VERSION ""

NS_ :

BS_:

BU_: XXX

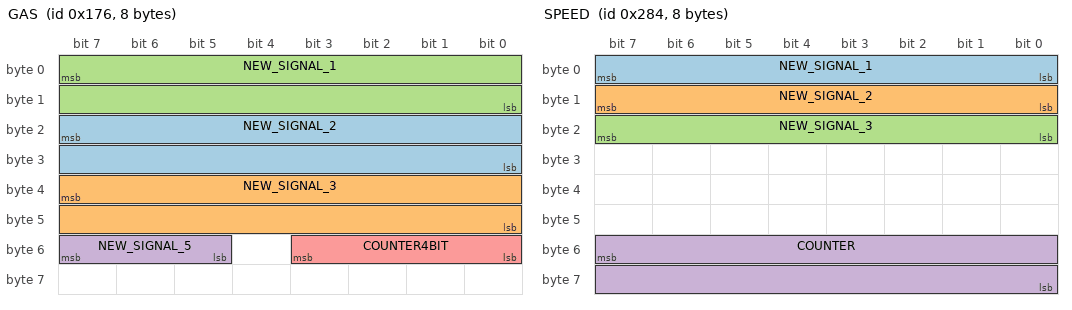
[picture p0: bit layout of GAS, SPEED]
BO_ 374 GAS: 8 XXX
 SG_ NEW_SIGNAL_2 : 23|16@0+ (1,0) [0|65535] "" XXX
 SG_ NEW_SIGNAL_3 : 39|16@0+ (1,0) [0|65535] "" XXX
 SG_ NEW_SIGNAL_1 : 7|16@0+ (1,0) [0|65535] "" XXX
 SG_ NEW_SIGNAL_5 : 55|3@0+ (1,0) [0|7] "" XXX
 SG_ COUNTER4BIT : 48|4@1+ (1,0) [0|15] "" XXX

BO_ 644 SPEED: 8 XXX
 SG_ NEW_SIGNAL_1 : 7|8@0+ (1,0) [0|65535] "" XXX
 SG_ NEW_SIGNAL_2 : 15|8@0+ (1,0) [0|255] "" XXX
 SG_ NEW_SIGNAL_3 : 23|8@0+ (1,0) [0|255] "" XXX
 SG_ COUNTER : 55|16@0+ (1,0) [0|65535] "" XXX

BO_ 658 NEW_MSG_2: 8 XXX
 SG_ NEW_SIGNAL_1 : 15|8@0+ (1,0) [0|255] "" XXX
 SG_ NEW_SIGNAL_2 : 7|8@0+ (1,0) [0|255] "" XXX
 SG_ NEW_SIGNAL_3 : 23|0@0+ (1,0) [0|255] "" XXX

BO_ 768 STEERING: 8 XXX
 SG_ STEER_TORQUE : 7|8@0+ (1,0) [0|255] "" XXX

BO_ 645 SPEED2: 8 XXX
 SG_ COUNTER : 55|16@0+ (1,0) [0|255] "" XXX
